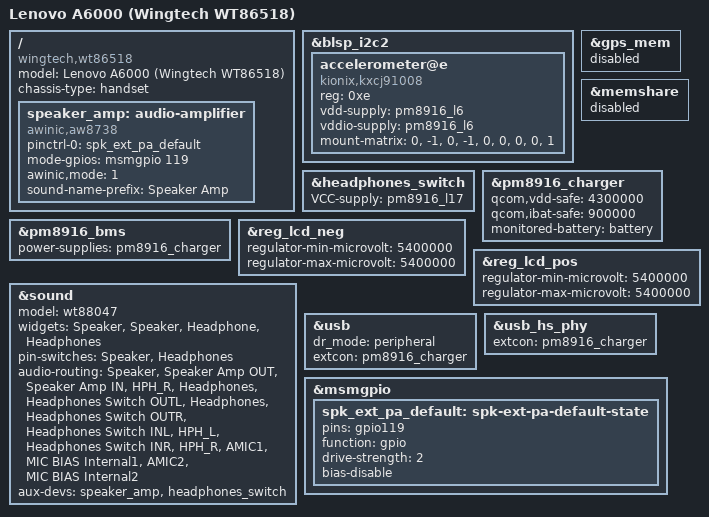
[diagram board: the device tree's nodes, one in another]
// SPDX-License-Identifier: GPL-2.0-only

/dts-v1/;

#include "msm8916-wingtech-wt865x8.dtsi"

/ {
	model = "Lenovo A6000 (Wingtech WT86518)";
	compatible = "wingtech,wt86518", "qcom,msm8916";
	chassis-type = "handset";

	speaker_amp: audio-amplifier {
		compatible = "awinic,aw8738";

		pinctrl-names = "default";
		pinctrl-0 = <&spk_ext_pa_default>;

		mode-gpios = <&msmgpio 119 GPIO_ACTIVE_HIGH>;
		awinic,mode = <1>;
		sound-name-prefix = "Speaker Amp";
	};
};

&blsp_i2c2 {
	accelerometer@e {
		compatible = "kionix,kxcj91008";
		reg = <0xe>;

		vdd-supply = <&pm8916_l6>;
		vddio-supply = <&pm8916_l6>;

		mount-matrix = "0", "-1", "0",
			       "-1", "0", "0",
			       "0",  "0", "1";
	};
};

&gps_mem {
	status = "disabled";
};

&headphones_switch {
	VCC-supply = <&pm8916_l17>;
};

&memshare {
	status = "disabled";
};

&pm8916_charger {
	qcom,vdd-safe = <4300000>;
	qcom,ibat-safe = <900000>;

	monitored-battery = <&battery>;

	status = "okay";
};

&pm8916_bms {
	power-supplies = <&pm8916_charger>;
};

&reg_lcd_neg {
	regulator-min-microvolt = <5400000>;
	regulator-max-microvolt = <5400000>;
};

&reg_lcd_pos {
	regulator-min-microvolt = <5400000>;
	regulator-max-microvolt = <5400000>;
};

&sound {
	status = "okay";

	model = "wt88047";
	widgets =
		"Speaker", "Speaker",
		"Headphone", "Headphones";
	pin-switches = "Speaker", "Headphones";
	audio-routing =
		"Speaker", "Speaker Amp OUT",
		"Speaker Amp IN", "HPH_R",
		"Headphones", "Headphones Switch OUTL",
		"Headphones", "Headphones Switch OUTR",
		"Headphones Switch INL", "HPH_L",
		"Headphones Switch INR", "HPH_R",
		"AMIC1", "MIC BIAS Internal1",
		"AMIC2", "MIC BIAS Internal2";
	aux-devs = <&speaker_amp>, <&headphones_switch>;
};

&usb {
	dr_mode = "peripheral";
	extcon = <&pm8916_charger>;
};

&usb_hs_phy {
	extcon = <&pm8916_charger>;
};

&msmgpio {
	spk_ext_pa_default: spk-ext-pa-default-state {
		pins = "gpio119";
		function = "gpio";

		drive-strength = <2>;
		bias-disable;
	};
};
